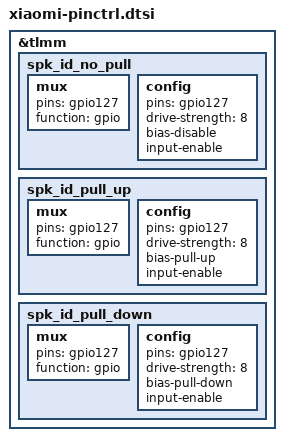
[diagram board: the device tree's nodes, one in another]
/* SPDX-License-Identifier: GPL-2.0-only */

&tlmm {
	spk_id_no_pull: spk_id_no_pull {
		mux {
			pins = "gpio127";
			function = "gpio";
		};

		config {
			pins = "gpio127";
			drive-strength = <8>;
			bias-disable;
			input-enable;
		};
	};

	spk_id_pull_up: spk_id_pull_up {
		mux {
			pins = "gpio127";
			function = "gpio";
		};

		config {
			pins = "gpio127";
			drive-strength = <8>;
			bias-pull-up;
			input-enable;
		};
	};

	spk_id_pull_down: spk_id_pull_down {
		mux {
			pins = "gpio127";
			function = "gpio";
		};

		config {
			pins = "gpio127";
			drive-strength = <8>;
			bias-pull-down;
			input-enable;
		};
	};
};
